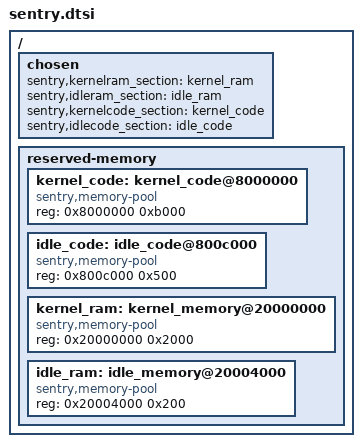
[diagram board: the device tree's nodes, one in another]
/*
 * Copyright (c) 2024  Ledger SAS
 *
 * SPDX-License-Identifier: Apache-2.0
 */

/{
	chosen {
		sentry,kernelram_section = <&kernel_ram>;
		sentry,idleram_section = <&idle_ram>;
		sentry,kernelcode_section = <&kernel_code>;
		sentry,idlecode_section = <&idle_code>;
	};

	reserved-memory {
		#address-cells = <1>;
		#size-cells = <1>;

		kernel_code: kernel_code@8000000 {
			reg = <0x8000000 0xb000>;
			compatible = "sentry,memory-pool";
		};

		idle_code: idle_code@800c000 {
			reg = <0x800c000 0x500>;
			compatible = "sentry,memory-pool";
		};

		kernel_ram: kernel_memory@20000000 {
			reg = <0x20000000 0x2000>;
			compatible = "sentry,memory-pool";
		};

		idle_ram: idle_memory@20004000 {
			reg = <0x20004000 0x200>;
			compatible = "sentry,memory-pool";
		};
	};
};
